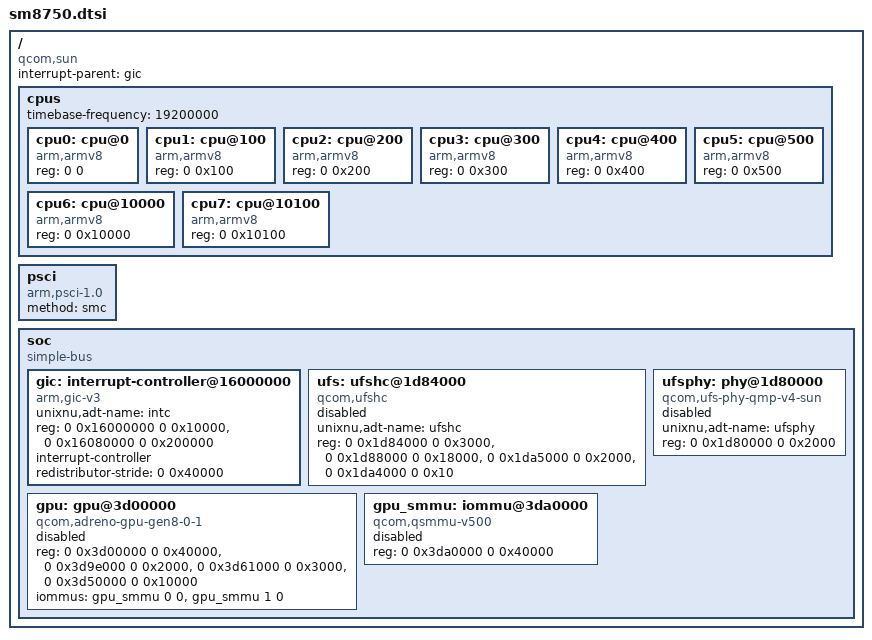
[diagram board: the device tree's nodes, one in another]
// SPDX-License-Identifier: BSD-3-Clause
// Qualcomm SM8750 (device-tree codename "sun") SoC skeleton.
//
// Every address below was read from THIS device's live device tree
// (Xiaomi Pad 8 Pro / piano, /sys/firmware/fdt, 1111735 B,
//  md5 d491cf2eec5f644043601dfc0014be09), not copied from SM8550.
//
// root compatible on the device: qcom,sun-mtp | qcom,sun | qcom,sunp-mtp | qcom,sunp | qcom,mtp
/ {
    compatible = "qcom,sun";
    #address-cells = <2>;
    #size-cells = <2>;
    interrupt-parent = <&gic>;

    cpus {
        #address-cells = <2>;
        #size-cells = <0>;
        timebase-frequency = <19200000>;

        // Oryon cores: no public ARM part number in the device tree,
        // every core reports compatible = "arm,armv8".
        cpu0: cpu@0     { device_type = "cpu"; compatible = "arm,armv8"; reg = <0 0>; };
        cpu1: cpu@100   { device_type = "cpu"; compatible = "arm,armv8"; reg = <0 0x100>; };
        cpu2: cpu@200   { device_type = "cpu"; compatible = "arm,armv8"; reg = <0 0x200>; };
        cpu3: cpu@300   { device_type = "cpu"; compatible = "arm,armv8"; reg = <0 0x300>; };
        cpu4: cpu@400   { device_type = "cpu"; compatible = "arm,armv8"; reg = <0 0x400>; };
        cpu5: cpu@500   { device_type = "cpu"; compatible = "arm,armv8"; reg = <0 0x500>; };
        cpu6: cpu@10000 { device_type = "cpu"; compatible = "arm,armv8"; reg = <0 0x10000>; };
        cpu7: cpu@10100 { device_type = "cpu"; compatible = "arm,armv8"; reg = <0 0x10100>; };
    };

    psci { compatible = "arm,psci-1.0"; method = "smc"; };

    soc {
        compatible = "simple-bus";
        #address-cells = <2>;
        #size-cells = <2>;
        ranges;

        // GICv3 at 0x16000000 on sun (SM8550 uses 0x17100000).
        gic: interrupt-controller@16000000 {
            compatible = "arm,gic-v3";
            unixnu,adt-name = "intc";
            reg = <0 0x16000000 0 0x10000>, <0 0x16080000 0 0x200000>;
            #interrupt-cells = <4>;
            #address-cells = <0>;
            interrupt-controller;
            redistributor-stride = <0 0x40000>;
        };

        ufs: ufshc@1d84000 {
            compatible = "qcom,ufshc";
            unixnu,adt-name = "ufshc";
            reg = <0 0x1d84000 0 0x3000>, <0 0x1d88000 0 0x18000>,
                  <0 0x1da5000 0 0x2000>, <0 0x1da4000 0 0x10>;
            status = "disabled";
        };

        ufsphy: phy@1d80000 {
            compatible = "qcom,ufs-phy-qmp-v4-sun";
            unixnu,adt-name = "ufsphy";
            reg = <0 0x1d80000 0 0x2000>;
            status = "disabled";
        };

        // Adreno 830 (gen8-0-1) on sun; SM8550 carries Adreno 740 instead.
        gpu: gpu@3d00000 {
            compatible = "qcom,adreno-gpu-gen8-0-1", "qcom,adreno";
            reg = <0 0x3d00000 0 0x40000>, <0 0x3d9e000 0 0x2000>,
                  <0 0x3d61000 0 0x3000>, <0 0x3d50000 0 0x10000>;
            reg-names = "kgsl_3d0_reg_memory", "cx_mem", "cx_dbgc", "gmu";
            iommus = <&gpu_smmu 0 0>, <&gpu_smmu 1 0>;
            status = "disabled";
        };

        gpu_smmu: iommu@3da0000 {
            compatible = "qcom,qsmmu-v500", "qcom,adreno-smmu", "qcom,smmu-500", "arm,mmu-500";
            reg = <0 0x3da0000 0 0x40000>;
            #iommu-cells = <2>;
            status = "disabled";
        };
    };
};
